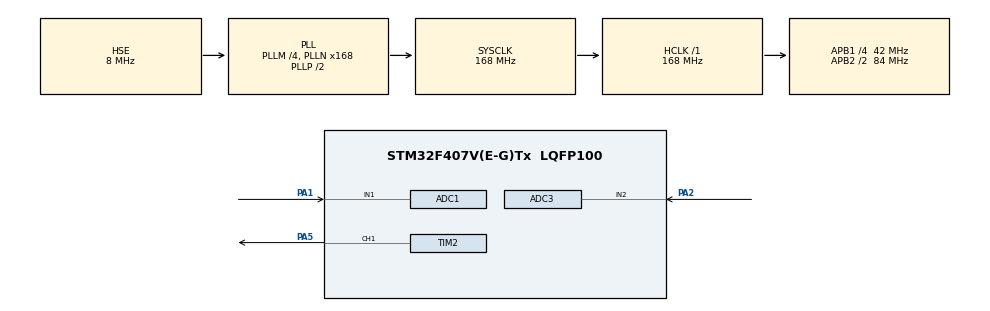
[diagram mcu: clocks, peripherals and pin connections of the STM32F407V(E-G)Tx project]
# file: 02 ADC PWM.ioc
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ADC1.Channel-1\#ChannelRegularConversion=ADC_CHANNEL_1
ADC1.NbrOfConversionFlag=1
ADC1.Rank-1\#ChannelRegularConversion=1
ADC1.Resolution=ADC_RESOLUTION_10B
ADC1.SamplingTime-1\#ChannelRegularConversion=ADC_SAMPLETIME_3CYCLES
ADC1.master=1
ADC3.Channel-4\#ChannelRegularConversion=ADC_CHANNEL_2
ADC3.NbrOfConversionFlag=1
ADC3.Rank-4\#ChannelRegularConversion=1
ADC3.Resolution=ADC_RESOLUTION_10B
ADC3.SamplingTime-4\#ChannelRegularConversion=ADC_SAMPLETIME_3CYCLES
Mcu.Family=STM32F4
Mcu.Name=STM32F407V(E-G)Tx
Mcu.Package=LQFP100
NVIC.PriorityGroup=NVIC_PRIORITYGROUP_0
PA1.Signal=ADCx_IN1
PA13.Mode=Serial_Wire
PA13.Signal=SYS_JTMS-SWDIO
PA14.Mode=Serial_Wire
PA14.Signal=SYS_JTCK-SWCLK
PA2.Signal=ADCx_IN2
PA5.Signal=S_TIM2_CH1_ETR
PH0-OSC_IN.Mode=HSE-External-Oscillator
PH0-OSC_IN.Signal=RCC_OSC_IN
PH1-OSC_OUT.Mode=HSE-External-Oscillator
PH1-OSC_OUT.Signal=RCC_OSC_OUT
ProjectManager.HeapSize=0x200
ProjectManager.StackSize=0x400
ProjectManager.TargetToolchain=MDK-ARM V5.32
RCC.48MHZClocksFreq_Value=48000000
RCC.AHBFreq_Value=168000000
RCC.APB1CLKDivider=RCC_HCLK_DIV4
RCC.APB1Freq_Value=42000000
RCC.APB1TimFreq_Value=84000000
RCC.APB2CLKDivider=RCC_HCLK_DIV2
RCC.APB2Freq_Value=84000000
RCC.APB2TimFreq_Value=168000000
RCC.CortexFreq_Value=168000000
RCC.HCLKFreq_Value=168000000
RCC.HSE_VALUE=8000000
RCC.HSI_VALUE=16000000
RCC.LSE_VALUE=32768
RCC.PLLM=4
RCC.PLLN=168
RCC.PLLQ=7
RCC.PLLSourceVirtual=RCC_PLLSOURCE_HSE
RCC.SYSCLKFreq_VALUE=168000000
RCC.SYSCLKSource=RCC_SYSCLKSOURCE_PLLCLK
RCC.VCOOutputFreq_Value=336000000
SH.ADCx_IN1.0=ADC1_IN1,IN1
SH.ADCx_IN2.0=ADC3_IN2,IN2
SH.S_TIM2_CH1_ETR.0=TIM2_CH1,PWM Generation1 CH1
TIM2.Channel-PWM\ Generation1\ CH1=TIM_CHANNEL_1
TIM2.Period=10000
TIM2.Prescaler=83
VP_TIM2_VS_ClockSourceINT.Mode=Internal
board=STM32F407G-DISC1

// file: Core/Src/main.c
/* USER CODE BEGIN Header */
/**
  ******************************************************************************
  * @file           : main.c
  * @brief          : Main program body
  ******************************************************************************
  * @attention
  *
  * Copyright (c) 2024 STMicroelectronics.
  * All rights reserved.
  *
  * This software is licensed under terms that can be found in the LICENSE file
  * in the root directory of this software component.
  * If no LICENSE file comes with this software, it is provided AS-IS.
  *
  ******************************************************************************
  */
/* USER CODE END Header */
#include "main.h"
#include "adc.h"
#include "tim.h"
#include "gpio.h"

void SystemClock_Config(void);

/* USER CODE BEGIN 0 */
int32_t adc1_value = 0;
int32_t adc3_value = 0;
int32_t read_adc1(void);
uint32_t read_adc3(void);
/* USER CODE END 0 */

int main(void)
{

  /* MCU Configuration--------------------------------------------------------*/

  /* Reset of all peripherals, Initializes the Flash interface and the Systick. */
  HAL_Init();

  /* Configure the system clock */
  SystemClock_Config();

  /* Initialize all configured peripherals */
  MX_GPIO_Init();
  MX_ADC1_Init();
  MX_TIM2_Init();
  MX_ADC3_Init();
  /* USER CODE BEGIN 2 */
	HAL_TIM_PWM_Start(&htim2, TIM_CHANNEL_1);
  /* USER CODE END 2 */

  /* Infinite loop */
  /* USER CODE BEGIN WHILE */
  while (1)
  {
		adc1_value = read_adc1();
		htim2.Instance->CCR1 = (adc1_value*0.001)*htim2.Instance->ARR;

		adc3_value = read_adc3();
		htim2.Instance->ARR = (uint32_t) ((adc3_value* 0.9775)+ 8999);

		HAL_Delay(100);
    /* USER CODE END WHILE */

  }
}

void SystemClock_Config(void)
{
  RCC_OscInitTypeDef RCC_OscInitStruct = {0};
  RCC_ClkInitTypeDef RCC_ClkInitStruct = {0};

  /** Configure the main internal regulator output voltage
  */
  __HAL_RCC_PWR_CLK_ENABLE();
  __HAL_PWR_VOLTAGESCALING_CONFIG(PWR_REGULATOR_VOLTAGE_SCALE1);

  /** Initializes the RCC Oscillators according to the specified parameters
  * in the RCC_OscInitTypeDef structure.
  */
  RCC_OscInitStruct.OscillatorType = RCC_OSCILLATORTYPE_HSE;
  RCC_OscInitStruct.HSEState = RCC_HSE_ON;
  RCC_OscInitStruct.PLL.PLLState = RCC_PLL_ON;
  RCC_OscInitStruct.PLL.PLLSource = RCC_PLLSOURCE_HSE;
  RCC_OscInitStruct.PLL.PLLM = 4;
  RCC_OscInitStruct.PLL.PLLN = 168;
  RCC_OscInitStruct.PLL.PLLP = RCC_PLLP_DIV2;
  RCC_OscInitStruct.PLL.PLLQ = 7;
  if (HAL_RCC_OscConfig(&RCC_OscInitStruct) != HAL_OK)
  {
    Error_Handler();
  }

  /** Initializes the CPU, AHB and APB buses clocks
  */
  RCC_ClkInitStruct.ClockType = RCC_CLOCKTYPE_HCLK|RCC_CLOCKTYPE_SYSCLK
                              |RCC_CLOCKTYPE_PCLK1|RCC_CLOCKTYPE_PCLK2;
  RCC_ClkInitStruct.SYSCLKSource = RCC_SYSCLKSOURCE_PLLCLK;
  RCC_ClkInitStruct.AHBCLKDivider = RCC_SYSCLK_DIV1;
  RCC_ClkInitStruct.APB1CLKDivider = RCC_HCLK_DIV4;
  RCC_ClkInitStruct.APB2CLKDivider = RCC_HCLK_DIV2;

  if (HAL_RCC_ClockConfig(&RCC_ClkInitStruct, FLASH_LATENCY_5) != HAL_OK)
  {
    Error_Handler();
  }
}

/* USER CODE BEGIN 4 */
int32_t read_adc1(void)
{
	HAL_ADC_Start(&hadc1);
	if(HAL_ADC_PollForConversion(&hadc1, 5) == HAL_OK) { return HAL_ADC_GetValue(&hadc1); }
	HAL_ADC_Stop(&hadc1);
	return -1;
}
uint32_t read_adc3(void)
{
	HAL_ADC_Start(&hadc3);
	if(HAL_ADC_PollForConversion(&hadc3, 5) == HAL_OK) { return HAL_ADC_GetValue(&hadc3); }
	HAL_ADC_Stop(&hadc3);
	return 0;
}
/* USER CODE END 4 */

void Error_Handler(void)
{
  __disable_irq();
  while (1)
  {
  }
}
